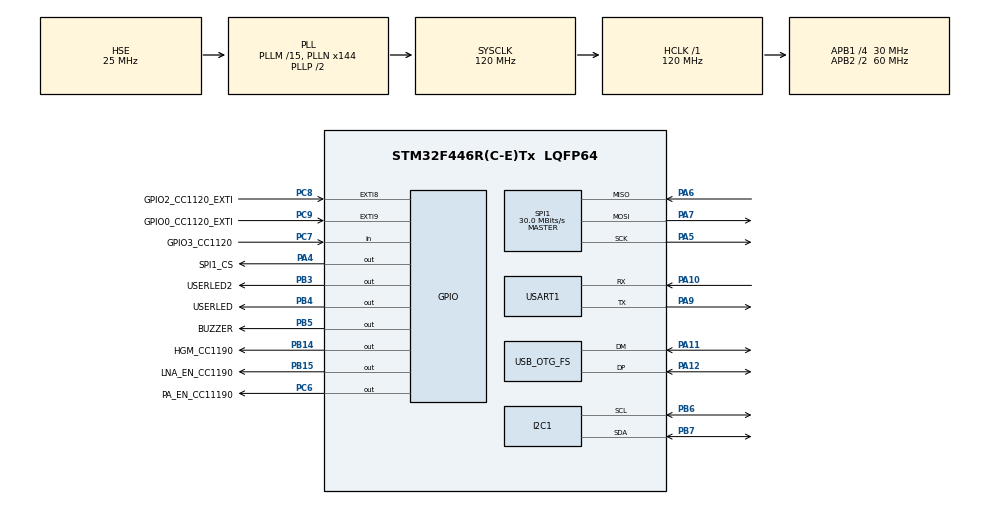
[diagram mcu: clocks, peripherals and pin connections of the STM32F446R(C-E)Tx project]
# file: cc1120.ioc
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Mcu.Family=STM32F4
Mcu.Name=STM32F446R(C-E)Tx
Mcu.Package=LQFP64
NVIC.EXTI9_5_IRQn=true\:0\:0\:false\:false\:true\:true\:true\:true
NVIC.OTG_FS_IRQn=true\:0\:0\:false\:false\:true\:false\:true\:true
NVIC.PriorityGroup=NVIC_PRIORITYGROUP_4
NVIC.TIM5_IRQn=true\:15\:0\:false\:false\:true\:false\:true\:true
NVIC.TimeBase=TIM5_IRQn
NVIC.TimeBaseIP=TIM5
PA10.Mode=Asynchronous
PA10.Signal=USART1_RX
PA11.Mode=Host_Only
PA11.Signal=USB_OTG_FS_DM
PA12.Mode=Host_Only
PA12.Signal=USB_OTG_FS_DP
PA13.Mode=Serial_Wire
PA13.Signal=SYS_JTMS-SWDIO
PA14.Mode=Serial_Wire
PA14.Signal=SYS_JTCK-SWCLK
PA4.GPIO_Label=SPI1_CS
PA4.Signal=GPIO_Output
PA5.Mode=Full_Duplex_Master
PA5.Signal=SPI1_SCK
PA6.Mode=Full_Duplex_Master
PA6.Signal=SPI1_MISO
PA7.Mode=Full_Duplex_Master
PA7.Signal=SPI1_MOSI
PA9.Mode=Asynchronous
PA9.Signal=USART1_TX
PB14.GPIO_Label=HGM_CC1190
PB14.Signal=GPIO_Output
PB15.GPIO_Label=LNA_EN_CC1190
PB15.Signal=GPIO_Output
PB3.GPIO_Label=USERLED2
PB3.Signal=GPIO_Output
PB4.GPIO_Label=USERLED
PB4.Signal=GPIO_Output
PB5.GPIO_Label=BUZZER
PB5.Signal=GPIO_Output
PB6.Mode=I2C
PB6.Signal=I2C1_SCL
PB7.Mode=I2C
PB7.Signal=I2C1_SDA
PC6.GPIO_Label=PA_EN_CC11190
PC6.Signal=GPIO_Output
PC7.GPIO_Label=GPIO3_CC1120
PC7.Signal=GPIO_Input
PC8.GPIO_Label=GPIO2_CC1120_EXTI
PC8.GPIO_ModeDefaultEXTI=GPIO_MODE_IT_FALLING
PC8.Signal=GPXTI8
PC9.GPIO_Label=GPIO0_CC1120_EXTI
PC9.GPIO_ModeDefaultEXTI=GPIO_MODE_IT_FALLING
PC9.Signal=GPXTI9
PH0-OSC_IN.Mode=HSE-External-Oscillator
PH0-OSC_IN.Signal=RCC_OSC_IN
PH1-OSC_OUT.Mode=HSE-External-Oscillator
PH1-OSC_OUT.Signal=RCC_OSC_OUT
ProjectManager.HeapSize=0x200
ProjectManager.StackSize=0x400
ProjectManager.TargetToolchain=STM32CubeIDE
RCC.AHBFreq_Value=120000000
RCC.APB1CLKDivider=RCC_HCLK_DIV4
RCC.APB1Freq_Value=30000000
RCC.APB1TimFreq_Value=60000000
RCC.APB2CLKDivider=RCC_HCLK_DIV2
RCC.APB2Freq_Value=60000000
RCC.APB2TimFreq_Value=120000000
RCC.CortexFreq_Value=120000000
RCC.HCLKFreq_Value=120000000
RCC.PLLM=15
RCC.PLLN=144
RCC.PLLQ=5
RCC.PLLSourceVirtual=RCC_PLLSOURCE_HSE
RCC.SYSCLKFreq_VALUE=120000000
RCC.SYSCLKSource=RCC_SYSCLKSOURCE_PLLCLK
RCC.USBFreq_Value=48000000
RCC.VCOOutputFreq_Value=240000000
SPI1.BaudRatePrescaler=SPI_BAUDRATEPRESCALER_2
SPI1.CLKPolarity=SPI_POLARITY_LOW
SPI1.CalculateBaudRate=30.0 MBits/s
SPI1.Direction=SPI_DIRECTION_2LINES
SPI1.Mode=SPI_MODE_MASTER
SPI1.VirtualType=VM_MASTER
USART1.VirtualMode=VM_ASYNC
USB_HOST.USBH_HandleTypeDef-CDC_FS=hUsbHostFS
USB_HOST.VirtualModeFS=Cdc
USB_OTG_FS.VirtualMode=Host_Only
USB_OTG_FS.phy_itface=HCD_PHY_EMBEDDED
VP_SYS_VS_tim5.Mode=TIM5
VP_USB_HOST_VS_USB_HOST_CDC_FS.Mode=CDC_FS
board=custom

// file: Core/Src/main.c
/* USER CODE BEGIN Header */
/**
 ******************************************************************************
 * @file           : main.c
 * @brief          : Main program body
 ******************************************************************************
 * @attention
 *
 * Copyright (c) 2024 STMicroelectronics.
 * All rights reserved.
 *
 * This software is licensed under terms that can be found in the LICENSE file
 * in the root directory of this software component.
 * If no LICENSE file comes with this software, it is provided AS-IS.
 *
 ******************************************************************************
 */
/* USER CODE END Header */
#include "main.h"
#include "i2c.h"
#include "spi.h"
#include "usart.h"
#include "usb_host.h"
#include "gpio.h"

/* USER CODE BEGIN Includes */
#include "cc1120_intf.h"

/* USER CODE END Includes */

/* USER CODE BEGIN PV */
cc1120_devTypeDef* cc1120_dev;
RfChipStatus_t chipstatus;
/* USER CODE END PV */

void SystemClock_Config(void);
void MX_USB_HOST_Process(void);

/* USER CODE BEGIN 0 */
void HAL_GPIO_EXTI_Callback(uint16_t GPIO_Pin) {
  //PKT_SYNC_RXTX
  if (GPIO_Pin == GPIO2_CC1120_EXTI_Pin) {

    if(cc1120_dev->rfmode == RF_MODE_RX){
      // Wait for packet received interrupt
      chipstatus = rfRecieveRxPacket();
      chipstatus = rfRunRx();
    }
    else{
      // Wait for interrupt that packet has been sent.
      //chipstatus = rfSendTxPacket();
      HAL_Delay(2);

    }
  }
  if (GPIO_Pin == GPIO0_CC1120_EXTI_Pin) {
    //RXFIFO_THR Handler
  }
}

/* USER CODE END 0 */

int main(void)
{

  /* MCU Configuration--------------------------------------------------------*/

  /* Reset of all peripherals, Initializes the Flash interface and the Systick. */
  HAL_Init();

  /* Configure the system clock */
  SystemClock_Config();

  /* Initialize all configured peripherals */
  MX_GPIO_Init();
  MX_SPI1_Init();
  MX_I2C1_Init();
  MX_USART1_UART_Init();
  MX_USB_HOST_Init();
  /* USER CODE BEGIN 2 */

  //Initialize CC1120
  //rfinit(cc1120_dev);

  /* USER CODE END 2 */

  /* Infinite loop */
  /* USER CODE BEGIN WHILE */
  while (1)
  {
	 majorTomHere();
    /* USER CODE END WHILE */
    MX_USB_HOST_Process();

  }
}

void SystemClock_Config(void)
{
  RCC_OscInitTypeDef RCC_OscInitStruct = {0};
  RCC_ClkInitTypeDef RCC_ClkInitStruct = {0};

  /** Configure the main internal regulator output voltage
  */
  __HAL_RCC_PWR_CLK_ENABLE();
  __HAL_PWR_VOLTAGESCALING_CONFIG(PWR_REGULATOR_VOLTAGE_SCALE3);

  /** Initializes the RCC Oscillators according to the specified parameters
  * in the RCC_OscInitTypeDef structure.
  */
  RCC_OscInitStruct.OscillatorType = RCC_OSCILLATORTYPE_HSE;
  RCC_OscInitStruct.HSEState = RCC_HSE_ON;
  RCC_OscInitStruct.PLL.PLLState = RCC_PLL_ON;
  RCC_OscInitStruct.PLL.PLLSource = RCC_PLLSOURCE_HSE;
  RCC_OscInitStruct.PLL.PLLM = 15;
  RCC_OscInitStruct.PLL.PLLN = 144;
  RCC_OscInitStruct.PLL.PLLP = RCC_PLLP_DIV2;
  RCC_OscInitStruct.PLL.PLLQ = 5;
  RCC_OscInitStruct.PLL.PLLR = 2;
  if (HAL_RCC_OscConfig(&RCC_OscInitStruct) != HAL_OK)
  {
    Error_Handler();
  }

  /** Initializes the CPU, AHB and APB buses clocks
  */
  RCC_ClkInitStruct.ClockType = RCC_CLOCKTYPE_HCLK|RCC_CLOCKTYPE_SYSCLK
                              |RCC_CLOCKTYPE_PCLK1|RCC_CLOCKTYPE_PCLK2;
  RCC_ClkInitStruct.SYSCLKSource = RCC_SYSCLKSOURCE_PLLCLK;
  RCC_ClkInitStruct.AHBCLKDivider = RCC_SYSCLK_DIV1;
  RCC_ClkInitStruct.APB1CLKDivider = RCC_HCLK_DIV4;
  RCC_ClkInitStruct.APB2CLKDivider = RCC_HCLK_DIV2;

  if (HAL_RCC_ClockConfig(&RCC_ClkInitStruct, FLASH_LATENCY_3) != HAL_OK)
  {
    Error_Handler();
  }
}

void HAL_TIM_PeriodElapsedCallback(TIM_HandleTypeDef *htim)
{
  if (htim->Instance == TIM5) {
    HAL_IncTick();
  }
}

void Error_Handler(void)
{
  __disable_irq();
  while (1)
  {
  }
}
